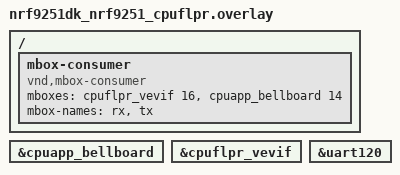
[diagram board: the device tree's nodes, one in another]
/*
 * Copyright 2026 Nordic Semiconductor ASA
 * SPDX-License-Identifier: Apache-2.0
 */

/ {
	mbox-consumer {
		compatible = "vnd,mbox-consumer";
		mboxes = <&cpuflpr_vevif 16>, <&cpuapp_bellboard 14>;
		mbox-names = "rx", "tx";
	};
};

&cpuapp_bellboard {
	status = "okay";
};

&cpuflpr_vevif {
	status = "okay";
};

&uart120 {
	/delete-property/ hw-flow-control;
};
